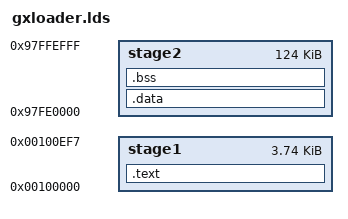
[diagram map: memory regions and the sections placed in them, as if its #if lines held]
#include "version_autogenerated.h"

MEMORY
{
	stage1	:	ORIGIN = 0x00100000,	LENGTH = 0x1000-264
	stage2	:	ORIGIN = 0x97fe0000,	LENGTH = 0x1f000
}
ENTRY(ResetEntry)
SECTIONS {
	. = ALIGN(4);
	.text :
	{
		cpu/ck/gx3201/gx3201_start.o(.text*)
		cpu/ck/gx3201/gx3201_pll_mini.o(.text*)
		cpu/ck/gx3201/gx3201_sdram.o(.text*)
		cpu/copy.o(.text*)
		cpu/ck/gx3201/gx3201_start.o(.rodata*)
		cpu/ck/gx3201/gx3201_pll_mini.o(.rodata*)
		cpu/ck/gx3201/gx3201_sdram.o(.rodata*)
		cpu/copy.o(.rodata*)
		cpu/ck/gx3201/gx3201_start.o(.data*)
		cpu/ck/gx3201/gx3201_pll_mini.o(.data*)
		cpu/ck/gx3201/gx3201_sdram.o(.data*)
		cpu/copy.o(.data*)
#ifdef CONFIG_ENABLE_MEMORY_PHASE_TEST
		test/memory/memphase_test.o(.text*)
		test/memory/memphase_test.o(.data*)
		test/memory/memphase_test.o(.rodata*)
#elif defined(CONFIG_ENABLE_MEMORY_TEST)
		test/memory/mem_test.o(.text*)
		test/memory/mem_test.o(.data*)
		test/memory/mem_test.o(.rodata*)
#endif
		*(.reset_patch)
		*(.sram_text)
		*(.sram)
	} > stage1

	. = ALIGN(2048);
	.data :
	{
		_stage2_start_ = .;
		_stage2_text_start_ = .;
		*(.irq_text)
		. = ALIGN(512);
		*(.fiq_text)
		. = ALIGN(512);
		*(.entry_text)
		. = ALIGN(4);
		*(.text*)
		. = ALIGN(4);
		_stage2_text_end_ = .;
		__commands_begin = .;
		KEEP(*(.data.commands))
		. = ALIGN(4);
		__commands_end = .;
		_stage2_data_start_ = .;
		*(.data*)
		*(.rodata*)
		. = ALIGN(16);
		_stage2_data_end_ = .;
	} > stage2

	. = ALIGN(4);
	.bss :
	{
		. = ALIGN(4);
		__bss_start__ = .;
		*(.bss*)
		*(COMMON)
		. = ALIGN(4);
		__bss_end__ = .;
	} > stage2

}

